# M051AN_v1 register map
File version: 1.0
Registers are 32-bit, read-write, reset 0x0 unless marked. A register's access mark holds for its fields unless they carry their own. Offsets are from the block's base; [hi:lo] are bit positions; {n}, {i} and the like mark numbered series; 'fields as' and 'values as' point back to an identical list.

## GP — GPIO Register Map
Base 0x50004000
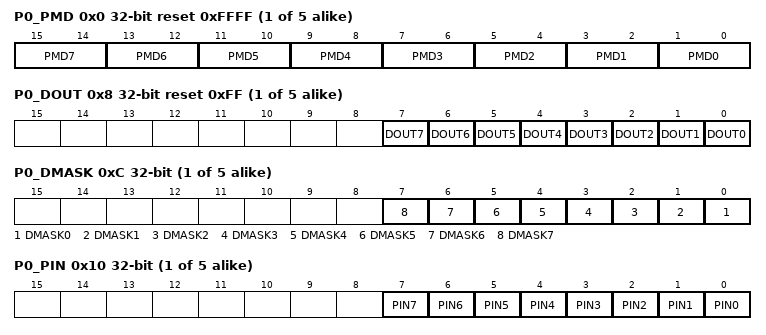
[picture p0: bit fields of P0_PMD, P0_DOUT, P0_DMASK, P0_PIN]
{0x0+0x40*i} P{i}_PMD reset 0xFFFF (i=0..4) — P{i} Pin I/O Mode Control
  [all] fields
    0=Px [n] pin is in INPUT mode; 1=Px [n] pin is in OUTPUT mode; 2=Px [n] pin is in Open-Drain mode; 3=Px [n] pin is in Quasi-bidirectional mode
  [2n+1:2n] PMD{n} (n=0..7) — Px I/O Pin[n] Mode Control. Determine each I/O type of Px pins
{0x4+0x40*i} P{i}_OFFD (i=0..4) — P{i} Bit OFF Digital Enable
  [23:16] OFFD — OFFD: Px Pin[n] OFF digital input path Enable
    0=Enable IO digital input path; 1=Disable IO digital input path (digital input tied to low)
{0x8+0x40*i} P{i}_DOUT reset 0xFF (i=0..4) — P{i} Data Output Value
  [all] fields
    0=Px Pin[n] will drive Low if the corresponding output mode enabling bit is set; 1=Px Pin[n] will drive High if the corresponding output mode enabling bit is set
  [n] DOUT{n} (n=0..7) — Px Pin[n] Output Value. Each of these bits control the status of a Px pin when the Px pin is configures as output, open-drain and quasi-mode.
{0xC+0x40*i} P{i}_DMASK (i=0..4) — P{i} Data Output Write Mask
  [all] fields
    0=The corresponding Px_DOUT[n] bit is not masked; 1=The corresponding Px_DOUT[n] bit is masked
  [n] DMASK{n} (n=0..7) — Px Data Output Write Mask. These bits are used to protect the corresponding register of Px_DOUT bit[n] . When set the DMASK bit[n] to "1", the corresponding Px_DOUT[n] bit is protected. The write signal is masked, write data to the protect bit is ignored
{0x10+0x40*i} P{i}_PIN ro (reset mask 0xFFFFFF00) (i=0..4) — P{i} Pin Value
  [n] PIN{n} (n=0..7) — Px Pin Values. The value read from each of these bit reflects the actual status of the respective Px pin
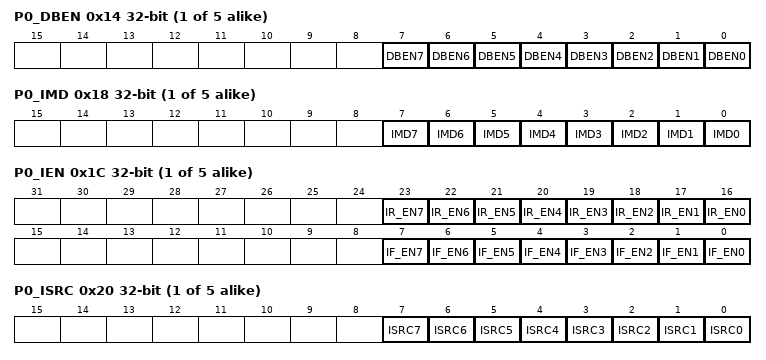
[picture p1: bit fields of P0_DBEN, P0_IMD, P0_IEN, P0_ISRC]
{0x14+0x40*i} P{i}_DBEN (i=0..4) — P{i} De-bounce Enable
  [all] fields
    0=The bit[n] de-bounce function is disabled; 1=The bit[n] de-bounce function is enabled
  [n] DBEN{n} (n=0..7) — Px Input Signal De-bounce Enable. DBEN[n]used to enable the de-bounce function for each corresponding bit. If the input signal pulse width can't be sampled by continuous two de-bounce sample cycle The input signal transition is seen as the signal bounce and will not trigger the interrupt. The DBEN[n] is used for "edge-trigger" interrupt only, and ignored for "level trigger" interrupt
{0x18+0x40*i} P{i}_IMD (i=0..4) — P{i} Interrupt Mode Control
  [all] fields
    0=Edge trigger interrupt; 1=Level trigger interrupt
  [n] IMD{n} (n=0..7) — Port 0-4 Interrupt Mode Control. IMD[n] used to control the interrupt is by level trigger or by edge trigger. If the interrupt is by edge trigger, the trigger source is control de-bounce. If the interrupt is by level trigger, the input source is sampled by one clock and the generate the interrupt
{0x1C+0x40*i} P{i}_IEN (i=0..4) — P{i} Interrupt Enable
  [n+16] IR_EN{n} (n=0..7) — Port 0-4 Interrupt Enable by Input Rising Edge or Input Level High. IR_EN[n] used to enable the interrupt for each of the corresponding input Px[n]. Set bit "1" also enable the pin wakeup function. When set the IR_EN[n] bit "1": If the interrupt is level mode trigger, the input Px[n] state at level "high" will generate the interrupt. If the interrupt is edge mode trigger, the input Px[n] state change from "low-to-high" will generate the interrupt.
    0=Disable the Px[n] level-high or low-to-high interrupt; 1=Enable the Px[n] level-high or low-to-high interrupt
  [n] IF_EN{n} (n=0..7) — Port 0-4 Interrupt Enable by Input Falling Edge or Input Level Low. IF_EN[n] used to enable the interrupt for each of the corresponding input Px[n]. Set bit "1" also enable the pin wakeup function. When set the IF_EN[n] bit "1": If the interrupt is level mode trigger, the input Px[n] state at level "low" will generate the interrupt. If the interrupt is edge mode trigger, the input Px[n] state change from "high-to-low" will generate the interrupt.
    0=Disable the Px[n] state low-level or high-to-low change interrupt; 1=Enable the Px[n] state low-level or high-to-low change interrupt
{0x20+0x40*i} P{i}_ISRC (i=0..4) — P{i} Interrupt Source Flag
  [all] fields
    0=No interrupt at Px[n]. No action; 1=Indicates Px[n] generate an interrupt. Clear the correspond pending interrupt
  [n] ISRC{n} (n=0..7) — Port 0-4 Interrupt Trigger Source Indicator. Read :
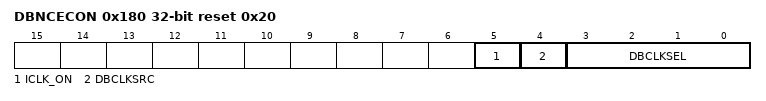
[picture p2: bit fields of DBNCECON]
0x180 DBNCECON reset 0x20 — External Interrupt De-bounce Control
  [5] ICLK_ON — Interrupt clock On mode. Set this bit "0" will disable the interrupt generate circuit clock, if the pin[n] interrupt is disabled
    0=disable the clock if the P0/1/2/3/4[n] interrupt is disabled; 1=interrupt generated circuit clock always enable
  [4] DBCLKSRC — De-bounce counter clock source select
    0=De-bounce counter clock source is the HCLK; 1=De-bounce counter clock source is the internal 10kHz low speed oscillator clock
  [3:0] DBCLKSEL — De-bounce sampling cycle selection
{0x200+4i} P{i:02}_PDIO (reset mask 0xFFFFFFF0) (i=0..7) — GPIO P0.n Pin Data Input/Output
  [0] Pxn_PDIO — GPIO Px.n Pin Data Input/Output. Write this bit can control one GPIO pin output value
    0=Set corresponding GPIO pin to low; 1=Set corresponding GPIO pin to high
{0x1F8+4i} P{i}_PDIO (reset mask 0xFFFFFFF0) (i=10..17) — GPIO P1.n Pin Data Input/Output
  fields as P00_PDIO
{0x1F0+4i} P{i}_PDIO (reset mask 0xFFFFFFF0) (i=20..27) — GPIO P2.n Pin Data Input/Output
  fields as P00_PDIO
{0x1E8+4i} P{i}_PDIO (reset mask 0xFFFFFFF0) (i=30..37) — GPIO P3.n Pin Data Input/Output
  fields as P00_PDIO
{0x1E0+4i} P{i}_PDIO (reset mask 0xFFFFFFF0) (i=40..47) — GPIO P4.n Pin Data Input/Output
  fields as P00_PDIO
